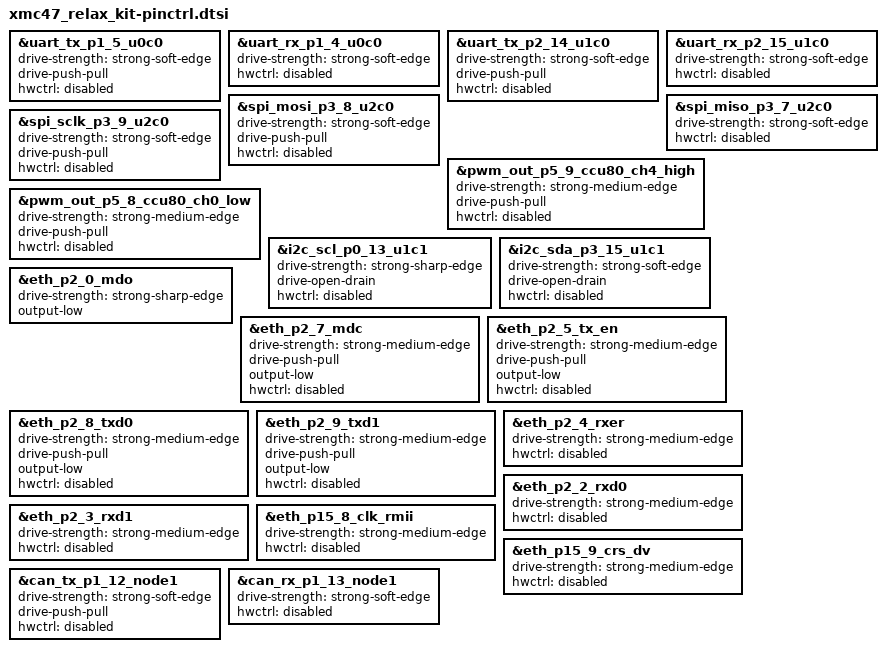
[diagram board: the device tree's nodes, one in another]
/*
 * Copyright (c) 2023 Schlumberger
 * SPDX-License-Identifier: Apache-2.0
 */

#include <infineon/cat3/xmc/xmc4700_F144x2048-pinctrl.dtsi>

&uart_tx_p1_5_u0c0 {
	drive-strength = "strong-soft-edge";
	drive-push-pull;
	hwctrl = "disabled";
};

&uart_rx_p1_4_u0c0 {
	drive-strength = "strong-soft-edge";
	hwctrl = "disabled";
};

&uart_tx_p2_14_u1c0 {
	drive-strength = "strong-soft-edge";
	drive-push-pull;
	hwctrl = "disabled";
};

&uart_rx_p2_15_u1c0 {
	drive-strength = "strong-soft-edge";
	hwctrl = "disabled";
};

&spi_mosi_p3_8_u2c0 {
	drive-strength = "strong-soft-edge";
	drive-push-pull;
	hwctrl = "disabled";
};

&spi_miso_p3_7_u2c0 {
	drive-strength = "strong-soft-edge";
	hwctrl = "disabled";
};

&spi_sclk_p3_9_u2c0 {
	drive-strength = "strong-soft-edge";
	drive-push-pull;
	hwctrl = "disabled";
};

&pwm_out_p5_9_ccu80_ch4_high {
	drive-strength = "strong-medium-edge";
	drive-push-pull;
	hwctrl = "disabled";
};

&pwm_out_p5_8_ccu80_ch0_low {
	drive-strength = "strong-medium-edge";
	drive-push-pull;
	hwctrl = "disabled";
};

&i2c_scl_p0_13_u1c1 {
	drive-strength = "strong-sharp-edge";
	drive-open-drain;
	hwctrl = "disabled";
};

&i2c_sda_p3_15_u1c1 {
	drive-strength = "strong-soft-edge";
	drive-open-drain;
	hwctrl = "disabled";
};

&eth_p2_0_mdo {
	drive-strength = "strong-sharp-edge";
	output-low;
};

&eth_p2_7_mdc {
	drive-strength = "strong-medium-edge";
	drive-push-pull;
	output-low;
	hwctrl = "disabled";
};

&eth_p2_5_tx_en {
	drive-strength = "strong-medium-edge";
	drive-push-pull;
	output-low;
	hwctrl = "disabled";
};

&eth_p2_8_txd0 {
	drive-strength = "strong-medium-edge";
	drive-push-pull;
	output-low;
	hwctrl = "disabled";
};

&eth_p2_9_txd1 {
	drive-strength = "strong-medium-edge";
	drive-push-pull;
	output-low;
	hwctrl = "disabled";
};

&eth_p2_4_rxer {
	drive-strength = "strong-medium-edge";
	hwctrl = "disabled";
};

&eth_p2_2_rxd0 {
	drive-strength = "strong-medium-edge";
	hwctrl = "disabled";
};

&eth_p2_3_rxd1 {
	drive-strength = "strong-medium-edge";
	hwctrl = "disabled";
};

&eth_p15_8_clk_rmii {
	drive-strength = "strong-medium-edge";
	hwctrl = "disabled";
};

&eth_p15_9_crs_dv {
	drive-strength = "strong-medium-edge";
	hwctrl = "disabled";
};

&can_tx_p1_12_node1 {
	drive-strength = "strong-soft-edge";
	drive-push-pull;
	hwctrl = "disabled";
};

&can_rx_p1_13_node1 {
	drive-strength = "strong-soft-edge";
	hwctrl = "disabled";
};
